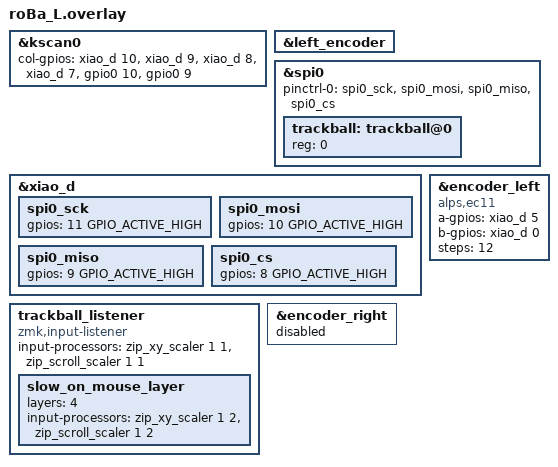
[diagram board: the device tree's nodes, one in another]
#include "roBa.dtsi"

&kscan0 {
        col-gpios
            = <&xiao_d 10 GPIO_ACTIVE_HIGH>
            , <&xiao_d 9 GPIO_ACTIVE_HIGH> 
            , <&xiao_d 8 GPIO_ACTIVE_HIGH> 
            , <&xiao_d 7 GPIO_ACTIVE_HIGH> 
            , <&gpio0 10 GPIO_ACTIVE_HIGH>
            , <&gpio0 9 GPIO_ACTIVE_HIGH>
            ;
};

&left_encoder {
    status = "okay";
};















/* roBa_L.overlay - Seeeduino XIAO BLE 用 */

/* ================= SPI0 (Trackball) ================= */
&spi0 {
    status = "okay";
    pinctrl-0 = <&spi0_sck &spi0_mosi &spi0_miso &spi0_cs>;
    pinctrl-names = "default";

    trackball: trackball@0 {
        status = "okay";
        reg = <0>;
    };
};

/* ================= SPI0 ピン設定 (XIAO D ピン番号例) ================= */
&xiao_d {
    spi0_sck: spi0_sck {
        gpios = <11 GPIO_ACTIVE_HIGH>;   /* SCK */
    };
    spi0_mosi: spi0_mosi {
        gpios = <10 GPIO_ACTIVE_HIGH>;   /* MOSI */
    };
    spi0_miso: spi0_miso {
        gpios = <9 GPIO_ACTIVE_HIGH>;    /* MISO */
    };
    spi0_cs: spi0_cs {
        gpios = <8 GPIO_ACTIVE_HIGH>;    /* CS */
    };
};

/* ================= Trackball listener ================= */
trackball_listener: trackball_listener {
    compatible = "zmk,input-listener";
    status = "okay";

    /* 通常時（全レイヤー共通） */
    input-processors = <
        &zip_xy_scaler 1 1
        &zip_scroll_scaler 1 1
    >;

    /* MOUSE レイヤー時は速度を半分に */
    slow_on_mouse_layer {
        layers = <4>;  /* MOUSE レイヤー番号 */
        input-processors = <
            &zip_xy_scaler 1 2
            &zip_scroll_scaler 1 2
        >;
    };
};

/* ================= 左右エンコーダ設定 ================= */
&encoder_left {
    compatible = "alps,ec11";
    a-gpios = <&xiao_d 5 (GPIO_ACTIVE_HIGH | GPIO_PULL_UP)>;
    b-gpios = <&xiao_d 0 (GPIO_ACTIVE_HIGH | GPIO_PULL_UP)>;
    steps = <12>;
    status = "okay";
};

&encoder_right {
    status = "disabled";
};
